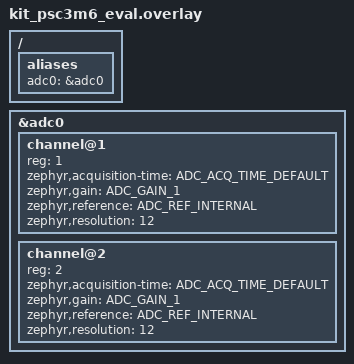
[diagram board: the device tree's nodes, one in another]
/*
 * SPDX-FileCopyrightText: Copyright (c) 2026 Infineon Technologies AG,
 * SPDX-FileCopyrightText: or an affiliate of Infineon Technologies AG. All rights reserved.
 *
 * SPDX-License-Identifier: Apache-2.0
 */

#include <zephyr/dt-bindings/adc/adc.h>

/ {
	aliases {
		adc0 = &adc0;
	};
};

&adc0 {
	/* AN_A1 and AN_A2 direct samplers. */
	channel@1 {
		reg = <1>;
		zephyr,acquisition-time = <ADC_ACQ_TIME_DEFAULT>;
		zephyr,gain = "ADC_GAIN_1";
		zephyr,reference = "ADC_REF_INTERNAL";
		zephyr,resolution = <12>;
	};

	channel@2 {
		reg = <2>;
		zephyr,acquisition-time = <ADC_ACQ_TIME_DEFAULT>;
		zephyr,gain = "ADC_GAIN_1";
		zephyr,reference = "ADC_REF_INTERNAL";
		zephyr,resolution = <12>;
	};
};
